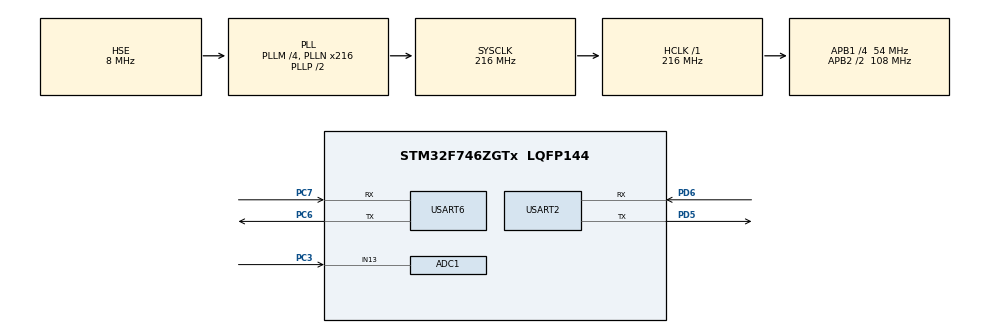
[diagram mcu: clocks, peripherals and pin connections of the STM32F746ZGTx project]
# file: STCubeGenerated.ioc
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ADC1.Channel-0\#ChannelRegularConversion=ADC_CHANNEL_13
ADC1.EOCSelection=ADC_EOC_SEQ_CONV
ADC1.NbrOfConversion=1
ADC1.NbrOfConversionFlag=1
ADC1.Rank-0\#ChannelRegularConversion=1
ADC1.SamplingTime-0\#ChannelRegularConversion=ADC_SAMPLETIME_56CYCLES
ADC1.ScanConvMode=ADC_SCAN_DISABLE
ADC1.master=1
CORTEX_M7.CPU_DCache=Enabled
CORTEX_M7.CPU_ICache=Enabled
CORTEX_M7.DisableExec-Cortex_Memory_Protection_Unit_Region0_Settings=MPU_INSTRUCTION_ACCESS_DISABLE
CORTEX_M7.Enable-Cortex_Memory_Protection_Unit_Region0_Settings=MPU_REGION_ENABLE
CORTEX_M7.IsShareable-Cortex_Memory_Protection_Unit_Region0_Settings=MPU_ACCESS_SHAREABLE
CORTEX_M7.MPU_Control=MPU_PRIVILEGED_DEFAULT
CORTEX_M7.PREFETCH_ENABLE=1
CORTEX_M7.Size-Cortex_Memory_Protection_Unit_Region0_Settings=MPU_REGION_SIZE_4GB
CORTEX_M7.SubRegionDisable-Cortex_Memory_Protection_Unit_Region0_Settings=0x87
Dma.Request0=USART6_RX
Dma.Request1=USART6_TX
Dma.Request2=USART2_RX
Dma.Request3=USART2_TX
Dma.USART2_RX.2.Direction=DMA_PERIPH_TO_MEMORY
Dma.USART2_RX.2.FIFOMode=DMA_FIFOMODE_DISABLE
Dma.USART2_RX.2.Instance=DMA1_Stream5
Dma.USART2_RX.2.MemDataAlignment=DMA_MDATAALIGN_BYTE
Dma.USART2_RX.2.MemInc=DMA_MINC_ENABLE
Dma.USART2_RX.2.Mode=DMA_CIRCULAR
Dma.USART2_RX.2.PeriphDataAlignment=DMA_PDATAALIGN_BYTE
Dma.USART2_RX.2.PeriphInc=DMA_PINC_DISABLE
Dma.USART2_RX.2.Priority=DMA_PRIORITY_LOW
Dma.USART2_TX.3.Direction=DMA_MEMORY_TO_PERIPH
Dma.USART2_TX.3.FIFOMode=DMA_FIFOMODE_DISABLE
Dma.USART2_TX.3.Instance=DMA1_Stream6
Dma.USART2_TX.3.MemDataAlignment=DMA_MDATAALIGN_BYTE
Dma.USART2_TX.3.MemInc=DMA_MINC_ENABLE
Dma.USART2_TX.3.Mode=DMA_NORMAL
Dma.USART2_TX.3.PeriphDataAlignment=DMA_PDATAALIGN_BYTE
Dma.USART2_TX.3.PeriphInc=DMA_PINC_DISABLE
Dma.USART2_TX.3.Priority=DMA_PRIORITY_LOW
Dma.USART6_RX.0.Direction=DMA_PERIPH_TO_MEMORY
Dma.USART6_RX.0.FIFOMode=DMA_FIFOMODE_ENABLE
Dma.USART6_RX.0.FIFOThreshold=DMA_FIFO_THRESHOLD_FULL
Dma.USART6_RX.0.Instance=DMA2_Stream1
Dma.USART6_RX.0.MemBurst=DMA_MBURST_SINGLE
Dma.USART6_RX.0.MemDataAlignment=DMA_MDATAALIGN_BYTE
Dma.USART6_RX.0.MemInc=DMA_MINC_ENABLE
Dma.USART6_RX.0.Mode=DMA_CIRCULAR
Dma.USART6_RX.0.PeriphBurst=DMA_PBURST_SINGLE
Dma.USART6_RX.0.PeriphDataAlignment=DMA_PDATAALIGN_BYTE
Dma.USART6_RX.0.PeriphInc=DMA_PINC_DISABLE
Dma.USART6_RX.0.Priority=DMA_PRIORITY_MEDIUM
Dma.USART6_TX.1.Direction=DMA_MEMORY_TO_PERIPH
Dma.USART6_TX.1.FIFOMode=DMA_FIFOMODE_ENABLE
Dma.USART6_TX.1.FIFOThreshold=DMA_FIFO_THRESHOLD_FULL
Dma.USART6_TX.1.Instance=DMA2_Stream6
Dma.USART6_TX.1.MemBurst=DMA_MBURST_SINGLE
Dma.USART6_TX.1.MemDataAlignment=DMA_MDATAALIGN_BYTE
Dma.USART6_TX.1.MemInc=DMA_MINC_ENABLE
Dma.USART6_TX.1.Mode=DMA_NORMAL
Dma.USART6_TX.1.PeriphBurst=DMA_PBURST_SINGLE
Dma.USART6_TX.1.PeriphDataAlignment=DMA_PDATAALIGN_BYTE
Dma.USART6_TX.1.PeriphInc=DMA_PINC_DISABLE
Dma.USART6_TX.1.Priority=DMA_PRIORITY_MEDIUM
Mcu.Family=STM32F7
Mcu.Name=STM32F746ZGTx
Mcu.Package=LQFP144
NVIC.DMA1_Stream5_IRQn=true\:0\:0\:false\:false\:true\:false\:true\:true
NVIC.DMA1_Stream6_IRQn=true\:0\:0\:false\:false\:true\:false\:true\:true
NVIC.DMA2_Stream1_IRQn=true\:0\:0\:false\:false\:true\:false\:true\:true
NVIC.DMA2_Stream6_IRQn=true\:0\:0\:false\:false\:true\:false\:true\:true
NVIC.PriorityGroup=NVIC_PRIORITYGROUP_4
NVIC.TIM6_DAC_IRQn=true\:15\:0\:false\:false\:true\:false\:true\:true
NVIC.TimeBase=TIM6_DAC_IRQn
NVIC.TimeBaseIP=TIM6
NVIC.USART2_IRQn=true\:0\:0\:false\:false\:true\:true\:true\:true
NVIC.USART6_IRQn=true\:0\:0\:false\:false\:true\:true\:true\:true
PC3.Signal=ADCx_IN13
PC6.Mode=Asynchronous
PC6.Signal=USART6_TX
PC7.Mode=Asynchronous
PC7.Signal=USART6_RX
PD5.Mode=Asynchronous
PD5.Signal=USART2_TX
PD6.Mode=Asynchronous
PD6.Signal=USART2_RX
PH0/OSC_IN.Mode=HSE-External-Clock-Source
PH0/OSC_IN.Signal=RCC_OSC_IN
PH1/OSC_OUT.Mode=HSE-External-Clock-Source
PH1/OSC_OUT.Signal=RCC_OSC_OUT
ProjectManager.HeapSize=0x200
ProjectManager.StackSize=0x400
ProjectManager.TargetToolchain=Makefile
RCC.AHBFreq_Value=216000000
RCC.APB1CLKDivider=RCC_HCLK_DIV4
RCC.APB1Freq_Value=54000000
RCC.APB1TimFreq_Value=108000000
RCC.APB2CLKDivider=RCC_HCLK_DIV2
RCC.APB2Freq_Value=108000000
RCC.APB2TimFreq_Value=216000000
RCC.CortexFreq_Value=216000000
RCC.HCLKFreq_Value=216000000
RCC.HSE_VALUE=8000000
RCC.HSI_VALUE=16000000
RCC.LSE_VALUE=32768
RCC.PLLM=4
RCC.PLLN=216
RCC.PLLSourceVirtual=RCC_PLLSOURCE_HSE
RCC.SYSCLKFreq_VALUE=216000000
RCC.SYSCLKSource=RCC_SYSCLKSOURCE_PLLCLK
RCC.USBFreq_Value=216000000
RCC.VCOOutputFreq_Value=432000000
SH.ADCx_IN13.0=ADC1_IN13,IN13
USART2.VirtualMode-Asynchronous=VM_ASYNC
USART6.VirtualMode-Asynchronous=VM_ASYNC
VP_CRC_VS_CRC.Mode=CRC_Activate
VP_SYS_VS_tim6.Mode=TIM6
board=custom

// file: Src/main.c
/* USER CODE BEGIN Header */
/**
  ******************************************************************************
  * @file           : main.c
  * @brief          : Main program body
  ******************************************************************************
  * @attention
  *
  * Copyright (c) 2024 STMicroelectronics.
  * All rights reserved.
  *
  * This software is licensed under terms that can be found in the LICENSE file
  * in the root directory of this software component.
  * If no LICENSE file comes with this software, it is provided AS-IS.
  *
  ******************************************************************************
  */
/* USER CODE END Header */
#include "main.h"

/* USER CODE BEGIN Includes */
#include "cmsis_os2.h"                  // CMSIS:RTOS2

/* USER CODE END Includes */

ADC_HandleTypeDef hadc1;

CRC_HandleTypeDef hcrc;

UART_HandleTypeDef huart2;
UART_HandleTypeDef huart6;
DMA_HandleTypeDef hdma_usart2_rx;
DMA_HandleTypeDef hdma_usart2_tx;
DMA_HandleTypeDef hdma_usart6_rx;
DMA_HandleTypeDef hdma_usart6_tx;

void SystemClock_Config(void);
static void MPU_Config(void);
static void MX_GPIO_Init(void);
static void MX_DMA_Init(void);
static void MX_USART6_UART_Init(void);
static void MX_USART2_UART_Init(void);
static void MX_ADC1_Init(void);
static void MX_CRC_Init(void);
/* USER CODE BEGIN PFP */
__NO_RETURN void mainThread(void * arg);
/* USER CODE END PFP */

int main(void)
{

  /* MPU Configuration--------------------------------------------------------*/
  MPU_Config();

  /* Enable the CPU Cache */

  /* Enable I-Cache---------------------------------------------------------*/
  SCB_EnableICache();

  /* Enable D-Cache---------------------------------------------------------*/
  SCB_EnableDCache();

  /* MCU Configuration--------------------------------------------------------*/

  /* Reset of all peripherals, Initializes the Flash interface and the Systick. */
  HAL_Init();

  /* Configure the system clock */
  SystemClock_Config();

  /* Initialize all configured peripherals */
  MX_GPIO_Init();
  MX_DMA_Init();
  MX_USART6_UART_Init();
  MX_USART2_UART_Init();
  MX_ADC1_Init();
  MX_CRC_Init();
  /* USER CODE BEGIN 2 */
  osKernelInitialize();
	osThreadNew(mainThread, NULL, NULL);
	osKernelStart();
  /* USER CODE END 2 */

  /* Infinite loop */
  while (1)
  {

  }
}

void SystemClock_Config(void)
{
  RCC_OscInitTypeDef RCC_OscInitStruct = {0};
  RCC_ClkInitTypeDef RCC_ClkInitStruct = {0};

  /** Configure the main internal regulator output voltage
  */
  __HAL_RCC_PWR_CLK_ENABLE();
  __HAL_PWR_VOLTAGESCALING_CONFIG(PWR_REGULATOR_VOLTAGE_SCALE1);

  /** Initializes the RCC Oscillators according to the specified parameters
  * in the RCC_OscInitTypeDef structure.
  */
  RCC_OscInitStruct.OscillatorType = RCC_OSCILLATORTYPE_HSE;
  RCC_OscInitStruct.HSEState = RCC_HSE_BYPASS;
  RCC_OscInitStruct.PLL.PLLState = RCC_PLL_ON;
  RCC_OscInitStruct.PLL.PLLSource = RCC_PLLSOURCE_HSE;
  RCC_OscInitStruct.PLL.PLLM = 4;
  RCC_OscInitStruct.PLL.PLLN = 216;
  RCC_OscInitStruct.PLL.PLLP = RCC_PLLP_DIV2;
  RCC_OscInitStruct.PLL.PLLQ = 2;
  if (HAL_RCC_OscConfig(&RCC_OscInitStruct) != HAL_OK)
  {
    Error_Handler();
  }

  /** Activate the Over-Drive mode
  */
  if (HAL_PWREx_EnableOverDrive() != HAL_OK)
  {
    Error_Handler();
  }

  /** Initializes the CPU, AHB and APB buses clocks
  */
  RCC_ClkInitStruct.ClockType = RCC_CLOCKTYPE_HCLK|RCC_CLOCKTYPE_SYSCLK
                              |RCC_CLOCKTYPE_PCLK1|RCC_CLOCKTYPE_PCLK2;
  RCC_ClkInitStruct.SYSCLKSource = RCC_SYSCLKSOURCE_PLLCLK;
  RCC_ClkInitStruct.AHBCLKDivider = RCC_SYSCLK_DIV1;
  RCC_ClkInitStruct.APB1CLKDivider = RCC_HCLK_DIV4;
  RCC_ClkInitStruct.APB2CLKDivider = RCC_HCLK_DIV2;

  if (HAL_RCC_ClockConfig(&RCC_ClkInitStruct, FLASH_LATENCY_7) != HAL_OK)
  {
    Error_Handler();
  }
}

static void MX_ADC1_Init(void)
{

  ADC_ChannelConfTypeDef sConfig = {0};

  /** Configure the global features of the ADC (Clock, Resolution, Data Alignment and number of conversion)
  */
  hadc1.Instance = ADC1;
  hadc1.Init.ClockPrescaler = ADC_CLOCK_SYNC_PCLK_DIV4;
  hadc1.Init.Resolution = ADC_RESOLUTION_12B;
  hadc1.Init.ScanConvMode = ADC_SCAN_DISABLE;
  hadc1.Init.ContinuousConvMode = DISABLE;
  hadc1.Init.DiscontinuousConvMode = DISABLE;
  hadc1.Init.ExternalTrigConvEdge = ADC_EXTERNALTRIGCONVEDGE_NONE;
  hadc1.Init.ExternalTrigConv = ADC_SOFTWARE_START;
  hadc1.Init.DataAlign = ADC_DATAALIGN_RIGHT;
  hadc1.Init.NbrOfConversion = 1;
  hadc1.Init.DMAContinuousRequests = DISABLE;
  hadc1.Init.EOCSelection = ADC_EOC_SEQ_CONV;
  if (HAL_ADC_Init(&hadc1) != HAL_OK)
  {
    Error_Handler();
  }

  /** Configure for the selected ADC regular channel its corresponding rank in the sequencer and its sample time.
  */
  sConfig.Channel = ADC_CHANNEL_13;
  sConfig.Rank = ADC_REGULAR_RANK_1;
  sConfig.SamplingTime = ADC_SAMPLETIME_56CYCLES;
  if (HAL_ADC_ConfigChannel(&hadc1, &sConfig) != HAL_OK)
  {
    Error_Handler();
  }

}

static void MX_CRC_Init(void)
{

  hcrc.Instance = CRC;
  hcrc.Init.DefaultPolynomialUse = DEFAULT_POLYNOMIAL_ENABLE;
  hcrc.Init.DefaultInitValueUse = DEFAULT_INIT_VALUE_ENABLE;
  hcrc.Init.InputDataInversionMode = CRC_INPUTDATA_INVERSION_NONE;
  hcrc.Init.OutputDataInversionMode = CRC_OUTPUTDATA_INVERSION_DISABLE;
  hcrc.InputDataFormat = CRC_INPUTDATA_FORMAT_BYTES;
  if (HAL_CRC_Init(&hcrc) != HAL_OK)
  {
    Error_Handler();
  }

}

static void MX_USART2_UART_Init(void)
{

  /* USER CODE BEGIN USART2_Init 0 */
#ifdef PRAKTIKUM
  /* USER CODE END USART2_Init 0 */

  huart2.Instance = USART2;
  huart2.Init.BaudRate = 115200;
  huart2.Init.WordLength = UART_WORDLENGTH_8B;
  huart2.Init.StopBits = UART_STOPBITS_1;
  huart2.Init.Parity = UART_PARITY_NONE;
  huart2.Init.Mode = UART_MODE_TX_RX;
  huart2.Init.HwFlowCtl = UART_HWCONTROL_NONE;
  huart2.Init.OverSampling = UART_OVERSAMPLING_16;
  huart2.Init.OneBitSampling = UART_ONE_BIT_SAMPLE_DISABLE;
  huart2.AdvancedInit.AdvFeatureInit = UART_ADVFEATURE_NO_INIT;
  if (HAL_UART_Init(&huart2) != HAL_OK)
  {
    Error_Handler();
  }
  /* USER CODE BEGIN USART2_Init 2 */
#endif
  /* USER CODE END USART2_Init 2 */

}

static void MX_USART6_UART_Init(void)
{

  /* USER CODE BEGIN USART6_Init 0 */
#ifdef LAUFLICHT
  /* USER CODE END USART6_Init 0 */

  huart6.Instance = USART6;
  huart6.Init.BaudRate = 115200;
  huart6.Init.WordLength = UART_WORDLENGTH_8B;
  huart6.Init.StopBits = UART_STOPBITS_1;
  huart6.Init.Parity = UART_PARITY_NONE;
  huart6.Init.Mode = UART_MODE_TX_RX;
  huart6.Init.HwFlowCtl = UART_HWCONTROL_NONE;
  huart6.Init.OverSampling = UART_OVERSAMPLING_16;
  huart6.Init.OneBitSampling = UART_ONE_BIT_SAMPLE_DISABLE;
  huart6.AdvancedInit.AdvFeatureInit = UART_ADVFEATURE_NO_INIT;
  if (HAL_UART_Init(&huart6) != HAL_OK)
  {
    Error_Handler();
  }
  /* USER CODE BEGIN USART6_Init 2 */
#endif
  /* USER CODE END USART6_Init 2 */

}

static void MX_DMA_Init(void)
{

  /* DMA controller clock enable */
  __HAL_RCC_DMA2_CLK_ENABLE();
  __HAL_RCC_DMA1_CLK_ENABLE();

  /* DMA interrupt init */
  /* DMA1_Stream5_IRQn interrupt configuration */
  HAL_NVIC_SetPriority(DMA1_Stream5_IRQn, 0, 0);
  HAL_NVIC_EnableIRQ(DMA1_Stream5_IRQn);
  /* DMA1_Stream6_IRQn interrupt configuration */
  HAL_NVIC_SetPriority(DMA1_Stream6_IRQn, 0, 0);
  HAL_NVIC_EnableIRQ(DMA1_Stream6_IRQn);
  /* DMA2_Stream1_IRQn interrupt configuration */
  HAL_NVIC_SetPriority(DMA2_Stream1_IRQn, 0, 0);
  HAL_NVIC_EnableIRQ(DMA2_Stream1_IRQn);
  /* DMA2_Stream6_IRQn interrupt configuration */
  HAL_NVIC_SetPriority(DMA2_Stream6_IRQn, 0, 0);
  HAL_NVIC_EnableIRQ(DMA2_Stream6_IRQn);

}

static void MX_GPIO_Init(void)
{

  /* GPIO Ports Clock Enable */
  __HAL_RCC_GPIOH_CLK_ENABLE();
  __HAL_RCC_GPIOC_CLK_ENABLE();
  __HAL_RCC_GPIOD_CLK_ENABLE();

}

 /* MPU Configuration */

void MPU_Config(void)
{
  MPU_Region_InitTypeDef MPU_InitStruct = {0};

  /* Disables the MPU */
  HAL_MPU_Disable();

  /** Initializes and configures the Region and the memory to be protected
  */
  MPU_InitStruct.Enable = MPU_REGION_ENABLE;
  MPU_InitStruct.Number = MPU_REGION_NUMBER0;
  MPU_InitStruct.BaseAddress = 0x0;
  MPU_InitStruct.Size = MPU_REGION_SIZE_4GB;
  MPU_InitStruct.SubRegionDisable = 0x87;
  MPU_InitStruct.TypeExtField = MPU_TEX_LEVEL0;
  MPU_InitStruct.AccessPermission = MPU_REGION_NO_ACCESS;
  MPU_InitStruct.DisableExec = MPU_INSTRUCTION_ACCESS_DISABLE;
  MPU_InitStruct.IsShareable = MPU_ACCESS_SHAREABLE;
  MPU_InitStruct.IsCacheable = MPU_ACCESS_NOT_CACHEABLE;
  MPU_InitStruct.IsBufferable = MPU_ACCESS_NOT_BUFFERABLE;

  HAL_MPU_ConfigRegion(&MPU_InitStruct);
  /* Enables the MPU */
  HAL_MPU_Enable(MPU_PRIVILEGED_DEFAULT);

}

void HAL_TIM_PeriodElapsedCallback(TIM_HandleTypeDef *htim)
{
  if (htim->Instance == TIM6) {
    HAL_IncTick();
  }
}

void Error_Handler(void)
{
  __disable_irq();
  while (1)
  {
  }
}
